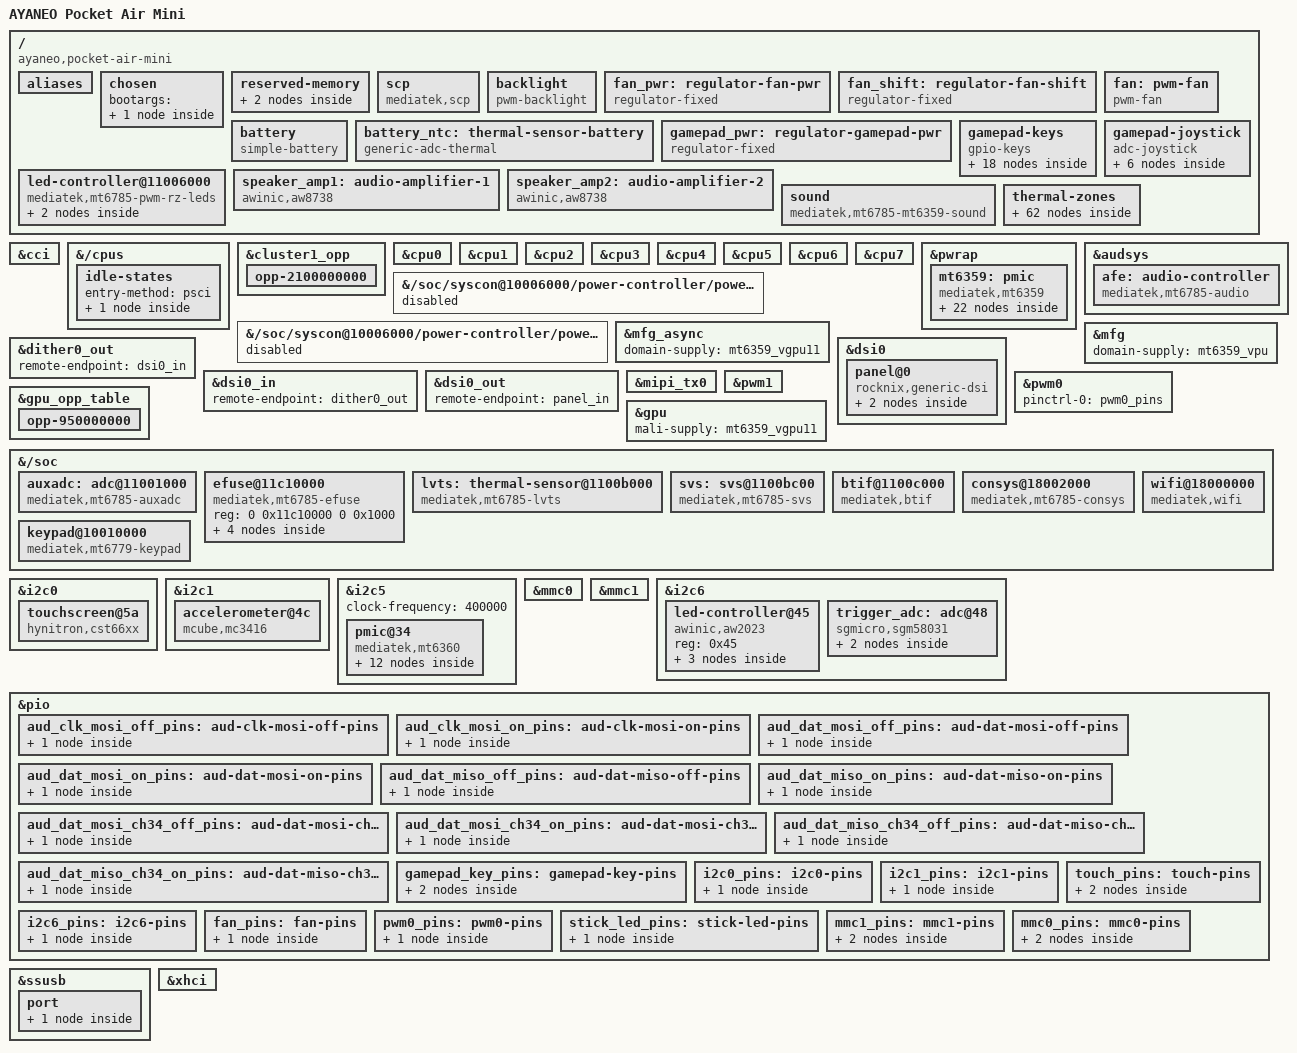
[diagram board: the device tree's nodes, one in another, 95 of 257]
// SPDX-License-Identifier: (GPL-2.0 OR MIT)
/dts-v1/;

#include <dt-bindings/gpio/gpio.h>
#include <dt-bindings/iio/adc/mediatek,mt6359-auxadc.h>
#include <dt-bindings/input/input.h>
#include <dt-bindings/leds/common.h>
#include <dt-bindings/thermal/mediatek,lvts-thermal.h>
#include <dt-bindings/thermal/thermal.h>
#include <dt-bindings/usb/pd.h>

#include "mt6785.dtsi"

/ {
	model = "AYANEO Pocket Air Mini";
	compatible = "ayaneo,pocket-air-mini", "mediatek,mt6785";
	chassis-type = "handset";

	/* eMMC probe waits for vemc, so pin the numbering */
	aliases {
		mmc0 = &mmc0;
		mmc1 = &mmc1;
	};

	chosen {
		#address-cells = <2>;
		#size-cells = <2>;
		ranges;

		/* needed by Little Kernel */
		bootargs = "";

		/* reg, stride and height are patched in by the custom LK (fdt_fixup_simplefb) */
		framebuffer0: framebuffer@7ed90000 {
			compatible = "simple-framebuffer";
			reg = <0 0x7ed90000 0 0x1070000>;
			width = <1280>;
			height = <3366>;
			stride = <(1280 * 4)>;
			format = "a8r8g8b8";
		};
	};

	/*
	 * No static reg nodes: LK appends its mblock-* regions here and hangs if one
	 * overlaps them. Dynamic size/alloc-ranges nodes are not checked.
	 */
	reserved-memory {
		#address-cells = <2>;
		#size-cells = <2>;
		ranges;

		consys_mem: consys-reserve-memory {
			compatible = "mediatek,consys-reserve-memory";
			no-map;
			size = <0 0x400000>;
			alignment = <0 0x1000000>;
			alloc-ranges = <0 0x40000000 0 0x80000000>;
		};

		wifi_mem: wifi-reserve-memory {
			compatible = "shared-dma-pool";
			no-map;
			size = <0 0x300000>;
			alignment = <0 0x1000000>;
			alloc-ranges = <0 0x40000000 0 0x80000000>;
		};
	};

	/* needed by Little Kernel */
	scp {
		compatible = "mediatek,scp";
	};

	/* DISP_PWM (GPIO42), keeping LK's 25.4 kHz */
	backlight: backlight {
		compatible = "pwm-backlight";
		pwms = <&pwm1 0 39385>;
		brightness-levels = <0 1023>;
		num-interpolated-steps = <1023>;
		default-brightness-level = <1023>;
	};

	/* fan power (GPIO22) feeds the level shifter enable (GPIO23) */
	fan_pwr: regulator-fan-pwr {
		compatible = "regulator-fixed";
		regulator-name = "fan_pwr";
		gpio = <&pio 22 GPIO_ACTIVE_HIGH>;
		enable-active-high;
	};

	fan_shift: regulator-fan-shift {
		compatible = "regulator-fixed";
		regulator-name = "fan_shift";
		gpio = <&pio 23 GPIO_ACTIVE_HIGH>;
		enable-active-high;
		vin-supply = <&fan_pwr>;
	};

	/* stock 1 kHz PWM, full speed for 50 ms to spin up */
	fan: pwm-fan {
		compatible = "pwm-fan";
		pwms = <&pwm0 0 1000000 0>;
		fan-supply = <&fan_shift>;
		interrupts-extended = <&pio 40 IRQ_TYPE_EDGE_FALLING>;
		pulses-per-revolution = <2>;
		fan-stop-to-start-percent = <100>;
		fan-stop-to-start-us = <50000>;
		#cooling-cells = <2>;
		cooling-levels = <0 77 128 191 255>;
		pinctrl-names = "default";
		pinctrl-0 = <&fan_pins>;
	};

	/* stock bat_gm30 and charger values, OCV from the 25 C profile */
	battery: battery {
		compatible = "simple-battery";
		device-chemistry = "lithium-ion";
		charge-full-design-microamp-hours = <4600000>;
		voltage-min-design-microvolt = <3400000>;
		voltage-max-design-microvolt = <4350000>;
		constant-charge-current-max-microamp = <2500000>;
		constant-charge-voltage-max-microvolt = <4350000>;
		charge-term-current-microamp = <150000>;
		precharge-current-microamp = <150000>;
		factory-internal-resistance-micro-ohms = <144000>;
		operating-range-celsius = <0 55>;
		ocv-capacity-celsius = <25>;
		ocv-capacity-table-0 = <4344900 100>,
				       <4257571 95>,
				       <4201313 90>,
				       <4147029 85>,
				       <4093285 80>,
				       <4048625 75>,
				       <3981883 70>,
				       <3939884 65>,
				       <3906996 60>,
				       <3866678 55>,
				       <3835200 50>,
				       <3811263 45>,
				       <3791581 40>,
				       <3775185 35>,
				       <3762021 30>,
				       <3749925 25>,
				       <3733298 20>,
				       <3709250 15>,
				       <3678882 10>,
				       <3656914 5>,
				       <3433700 0>;
	};

	/* 10k NTC with a 24k pull-up to VBIF28, AUXADC value in mV * 4096 */
	battery_ntc: thermal-sensor-battery {
		compatible = "generic-adc-thermal";
		#thermal-sensor-cells = <0>;
		io-channels = <&mt6359_auxadc MT6359_AUXADC_BAT_TEMP>;
		io-channel-names = "sensor-channel";
		temperature-lookup-table = <(-40000) 10215676>,
					   <(-35000) 9870092>,
					   <(-30000) 9464743>,
					   <(-25000) 9001485>,
					   <(-20000) 8484627>,
					   <(-15000) 7924032>,
					   <(-10000) 7330058>,
					   <(-5000) 6714236>,
					   <0 6094794>,
					   <5000 5487809>,
					   <10000 4903633>,
					   <15000 4351584>,
					   <20000 3840098>,
					   <25000 3373176>,
					   <30000 2951047>,
					   <35000 2574810>,
					   <40000 2242709>,
					   <45000 1950136>,
					   <50000 1694602>,
					   <55000 1472388>,
					   <60000 1279594>;
	};

	/* gamepad power, sequenced like the stock mtk-gamepad probe */
	gamepad_pwr: regulator-gamepad-pwr {
		compatible = "regulator-fixed";
		regulator-name = "gamepad_pwr";
		gpio = <&pio 15 GPIO_ACTIVE_HIGH>;
		enable-active-high;
		startup-delay-us = <100000>;
		vin-supply = <&mt6360_vfp>;
		regulator-always-on;
	};

	/* Start/Select codes as stock, D-pad as buttons */
	gamepad-keys {
		compatible = "gpio-keys";
		label = "Pocket Air Mini Buttons";
		pinctrl-names = "default";
		pinctrl-0 = <&gamepad_key_pins>;

		button-a {
			label = "a";
			linux,code = <BTN_SOUTH>;
			gpios = <&pio 82 GPIO_ACTIVE_LOW>;
		};

		button-b {
			label = "b";
			linux,code = <BTN_EAST>;
			gpios = <&pio 83 GPIO_ACTIVE_LOW>;
		};

		button-x {
			label = "x";
			linux,code = <BTN_NORTH>;
			gpios = <&pio 84 GPIO_ACTIVE_LOW>;
		};

		button-y {
			label = "y";
			linux,code = <BTN_WEST>;
			gpios = <&pio 85 GPIO_ACTIVE_LOW>;
		};

		button-lb {
			label = "lb";
			linux,code = <BTN_TL>;
			gpios = <&pio 92 GPIO_ACTIVE_LOW>;
		};

		button-rb {
			label = "rb";
			linux,code = <BTN_TR>;
			gpios = <&pio 81 GPIO_ACTIVE_LOW>;
		};

		button-l3 {
			label = "l3";
			linux,code = <BTN_THUMBL>;
			gpios = <&pio 94 GPIO_ACTIVE_LOW>;
		};

		button-r3 {
			label = "r3";
			linux,code = <BTN_THUMBR>;
			gpios = <&pio 93 GPIO_ACTIVE_LOW>;
		};

		button-select {
			label = "select";
			linux,code = <BTN_SELECT>;
			gpios = <&pio 90 GPIO_ACTIVE_LOW>;
		};

		button-start {
			label = "start";
			linux,code = <BTN_START>;
			gpios = <&pio 91 GPIO_ACTIVE_LOW>;
		};

		button-dpad-up {
			label = "dpad-up";
			linux,code = <BTN_DPAD_UP>;
			gpios = <&pio 89 GPIO_ACTIVE_LOW>;
		};

		button-dpad-down {
			label = "dpad-down";
			linux,code = <BTN_DPAD_DOWN>;
			gpios = <&pio 79 GPIO_ACTIVE_LOW>;
		};

		button-dpad-left {
			label = "dpad-left";
			linux,code = <BTN_DPAD_LEFT>;
			gpios = <&pio 78 GPIO_ACTIVE_LOW>;
		};

		button-dpad-right {
			label = "dpad-right";
			linux,code = <BTN_DPAD_RIGHT>;
			gpios = <&pio 80 GPIO_ACTIVE_LOW>;
		};

		button-aya {
			label = "aya";
			linux,code = <BTN_MODE>;
			gpios = <&pio 86 GPIO_ACTIVE_LOW>;
		};

		button-extra {
			label = "extra";
			linux,code = <BTN_TRIGGER_HAPPY1>;
			gpios = <&pio 87 GPIO_ACTIVE_LOW>;
		};

		button-lc {
			label = "lc";
			linux,code = <BTN_TRIGGER_HAPPY2>;
			gpios = <&pio 58 GPIO_ACTIVE_LOW>;
		};

		button-rc {
			label = "rc";
			linux,code = <BTN_TRIGGER_HAPPY3>;
			gpios = <&pio 57 GPIO_ACTIVE_LOW>;
		};
	};

	/* sticks on AUXADC 1-4, hall triggers on the SGM58031; Y axes and RT read inverted */
	gamepad-joystick {
		compatible = "adc-joystick";
		io-channels = <&auxadc 1>, <&auxadc 2>, <&auxadc 3>, <&auxadc 4>,
			      <&trigger_adc 4>, <&trigger_adc 5>;
		poll-interval = <8>;
		#address-cells = <1>;
		#size-cells = <0>;

		axis@0 {
			reg = <0>;
			linux,code = <ABS_X>;
			abs-range = <1170 3270>;
			abs-fuzz = <16>;
			abs-flat = <80>;
		};

		axis@1 {
			reg = <1>;
			linux,code = <ABS_Y>;
			abs-range = <3070 1170>;
			abs-fuzz = <16>;
			abs-flat = <80>;
		};

		axis@2 {
			reg = <2>;
			linux,code = <ABS_RX>;
			abs-range = <1094 3294>;
			abs-fuzz = <16>;
			abs-flat = <80>;
		};

		axis@3 {
			reg = <3>;
			linux,code = <ABS_RY>;
			abs-range = <3125 1145>;
			abs-fuzz = <16>;
			abs-flat = <80>;
		};

		axis@4 {
			reg = <4>;
			linux,code = <ABS_Z>;
			abs-range = <13700 16500>;
			abs-fuzz = <32>;
			abs-flat = <0>;
		};

		axis@5 {
			reg = <5>;
			linux,code = <ABS_RZ>;
			abs-range = <12550 10600>;
			abs-fuzz = <32>;
			abs-flat = <0>;
		};
	};

	/*
	 * 8 WS2812-style LEDs per stick ring on PWM_1 (left) and PWM_2 (right), in the
	 * PWM block shared with pwm-mediatek (fan on PWM_0)
	 */
	led-controller@11006000 {
		compatible = "mediatek,mt6785-pwm-rz-leds";
		reg = <0 0x11006000 0 0x1000>;
		clocks = <&infracfg CLK_INFRA_PWM>,
			 <&infracfg CLK_INFRA_PWM_HCLK>,
			 <&infracfg CLK_INFRA_PWM2>,
			 <&infracfg CLK_INFRA_PWM3>;
		clock-names = "top", "main", "pwm2", "pwm3";
		power-gpios = <&pio 127 GPIO_ACTIVE_HIGH>;
		enable-gpios = <&pio 202 GPIO_ACTIVE_HIGH>;
		pinctrl-names = "default";
		pinctrl-0 = <&stick_led_pins>;
		#address-cells = <1>;
		#size-cells = <0>;

		led@1 {
			reg = <1>;
			mediatek,num-leds = <8>;
			color = <LED_COLOR_ID_RGB>;
			function = "left-stick";
		};

		led@2 {
			reg = <2>;
			mediatek,num-leds = <8>;
			color = <LED_COLOR_ID_RGB>;
			function = "right-stick";
		};
	};

	/* two one-wire amps on the MT6359 headphone outputs, pulsed twice on enable */
	speaker_amp1: audio-amplifier-1 {
		compatible = "awinic,aw8738";
		mode-gpios = <&pio 24 GPIO_ACTIVE_HIGH>;
		awinic,mode = <2>;
		sound-name-prefix = "Speaker 1";
	};

	speaker_amp2: audio-amplifier-2 {
		compatible = "awinic,aw8738";
		mode-gpios = <&pio 21 GPIO_ACTIVE_HIGH>;
		awinic,mode = <2>;
		sound-name-prefix = "Speaker 2";
	};

	sound {
		compatible = "mediatek,mt6785-mt6359-sound";
		model = "PocketAirMini";
		mediatek,platform = <&afe>;
		mediatek,accdet = <&accdet>;
		aux-devs = <&speaker_amp1>, <&speaker_amp2>;
		audio-routing =
			"Headphone Jack", "Headphone L",
			"Headphone Jack", "Headphone R",
			"Speaker 1 IN", "Headphone L Ext Spk Amp",
			"Speaker 2 IN", "Headphone R Ext Spk Amp",
			"Speakers", "Speaker 1 OUT",
			"Speakers", "Speaker 2 OUT",
			"AIN0", "Internal Mic",
			"AIN1", "Headset Mic";
		pinctrl-names = "aud_clk_mosi_off", "aud_clk_mosi_on",
				"aud_dat_mosi_off", "aud_dat_mosi_on",
				"aud_dat_miso_off", "aud_dat_miso_on",
				"aud_dat_mosi_ch34_off", "aud_dat_mosi_ch34_on",
				"aud_dat_miso_ch34_off", "aud_dat_miso_ch34_on";
		pinctrl-0 = <&aud_clk_mosi_off_pins>;
		pinctrl-1 = <&aud_clk_mosi_on_pins>;
		pinctrl-2 = <&aud_dat_mosi_off_pins>;
		pinctrl-3 = <&aud_dat_mosi_on_pins>;
		pinctrl-4 = <&aud_dat_miso_off_pins>;
		pinctrl-5 = <&aud_dat_miso_on_pins>;
		pinctrl-6 = <&aud_dat_mosi_ch34_off_pins>;
		pinctrl-7 = <&aud_dat_mosi_ch34_on_pins>;
		pinctrl-8 = <&aud_dat_miso_ch34_off_pins>;
		pinctrl-9 = <&aud_dat_miso_ch34_on_pins>;
	};

	thermal-zones {
		battery-thermal {
			polling-delay-passive = <0>;
			polling-delay = <5000>;
			thermal-sensors = <&battery_ntc>;
		};

		cpu-big0-thermal {
			polling-delay-passive = <100>;
			polling-delay = <1000>;
			thermal-sensors = <&lvts MT6785_BIG_CPU0>;

			trips {
				big0_fan0: trip-fan0 {
					temperature = <55000>;
					hysteresis = <5000>;
					type = "active";
				};

				big0_fan1: trip-fan1 {
					temperature = <62000>;
					hysteresis = <5000>;
					type = "active";
				};

				big0_fan2: trip-fan2 {
					temperature = <69000>;
					hysteresis = <5000>;
					type = "active";
				};

				big0_fan3: trip-fan3 {
					temperature = <76000>;
					hysteresis = <5000>;
					type = "active";
				};

				big0_alert: trip-alert {
					temperature = <85000>;
					hysteresis = <2000>;
					type = "passive";
				};

				trip-crit {
					temperature = <117000>;
					hysteresis = <0>;
					type = "critical";
				};
			};

			cooling-maps {
				map0 {
					trip = <&big0_alert>;
					cooling-device = <&cpu6 THERMAL_NO_LIMIT THERMAL_NO_LIMIT>,
							 <&cpu7 THERMAL_NO_LIMIT THERMAL_NO_LIMIT>;
				};

				map1 {
					trip = <&big0_fan0>;
					cooling-device = <&fan 1 1>;
				};

				map2 {
					trip = <&big0_fan1>;
					cooling-device = <&fan 2 2>;
				};

				map3 {
					trip = <&big0_fan2>;
					cooling-device = <&fan 3 3>;
				};

				map4 {
					trip = <&big0_fan3>;
					cooling-device = <&fan 4 4>;
				};
			};
		};

		cpu-big1-thermal {
			polling-delay-passive = <100>;
			polling-delay = <1000>;
			thermal-sensors = <&lvts MT6785_BIG_CPU1>;

			trips {
				big1_alert: trip-alert {
					temperature = <85000>;
					hysteresis = <2000>;
					type = "passive";
				};

				trip-crit {
					temperature = <117000>;
					hysteresis = <0>;
					type = "critical";
				};
			};

			cooling-maps {
				map0 {
					trip = <&big1_alert>;
					cooling-device = <&cpu6 THERMAL_NO_LIMIT THERMAL_NO_LIMIT>,
							 <&cpu7 THERMAL_NO_LIMIT THERMAL_NO_LIMIT>;
				};
			};
		};

		cpu-little0-thermal {
			polling-delay-passive = <100>;
			polling-delay = <1000>;
			thermal-sensors = <&lvts MT6785_LITTLE_CPU0>;

			trips {
				little0_alert: trip-alert {
					temperature = <85000>;
					hysteresis = <2000>;
					type = "passive";
				};

				trip-crit {
					temperature = <117000>;
					hysteresis = <0>;
					type = "critical";
				};
			};

			cooling-maps {
				map0 {
					trip = <&little0_alert>;
					cooling-device = <&cpu0 THERMAL_NO_LIMIT THERMAL_NO_LIMIT>,
							 <&cpu1 THERMAL_NO_LIMIT THERMAL_NO_LIMIT>,
							 <&cpu2 THERMAL_NO_LIMIT THERMAL_NO_LIMIT>,
							 <&cpu3 THERMAL_NO_LIMIT THERMAL_NO_LIMIT>,
							 <&cpu4 THERMAL_NO_LIMIT THERMAL_NO_LIMIT>,
							 <&cpu5 THERMAL_NO_LIMIT THERMAL_NO_LIMIT>;
				};
			};
		};

		cpu-little1-thermal {
			polling-delay-passive = <100>;
			polling-delay = <1000>;
			thermal-sensors = <&lvts MT6785_LITTLE_CPU1>;

			trips {
				little1_alert: trip-alert {
					temperature = <85000>;
					hysteresis = <2000>;
					type = "passive";
				};

				trip-crit {
					temperature = <117000>;
					hysteresis = <0>;
					type = "critical";
				};
			};

			cooling-maps {
				map0 {
					trip = <&little1_alert>;
					cooling-device = <&cpu0 THERMAL_NO_LIMIT THERMAL_NO_LIMIT>,
							 <&cpu1 THERMAL_NO_LIMIT THERMAL_NO_LIMIT>,
							 <&cpu2 THERMAL_NO_LIMIT THERMAL_NO_LIMIT>,
							 <&cpu3 THERMAL_NO_LIMIT THERMAL_NO_LIMIT>,
							 <&cpu4 THERMAL_NO_LIMIT THERMAL_NO_LIMIT>,
							 <&cpu5 THERMAL_NO_LIMIT THERMAL_NO_LIMIT>;
				};
			};
		};

		cpu-little2-thermal {
			polling-delay-passive = <100>;
			polling-delay = <1000>;
			thermal-sensors = <&lvts MT6785_LITTLE_CPU2>;

			trips {
				little2_alert: trip-alert {
					temperature = <85000>;
					hysteresis = <2000>;
					type = "passive";
				};

				trip-crit {
					temperature = <117000>;
					hysteresis = <0>;
					type = "critical";
				};
			};

			cooling-maps {
				map0 {
					trip = <&little2_alert>;
					cooling-device = <&cpu0 THERMAL_NO_LIMIT THERMAL_NO_LIMIT>,
							 <&cpu1 THERMAL_NO_LIMIT THERMAL_NO_LIMIT>,
							 <&cpu2 THERMAL_NO_LIMIT THERMAL_NO_LIMIT>,
							 <&cpu3 THERMAL_NO_LIMIT THERMAL_NO_LIMIT>,
							 <&cpu4 THERMAL_NO_LIMIT THERMAL_NO_LIMIT>,
							 <&cpu5 THERMAL_NO_LIMIT THERMAL_NO_LIMIT>;
				};
			};
		};

		gpu0-thermal {
			polling-delay-passive = <100>;
			polling-delay = <1000>;
			thermal-sensors = <&lvts MT6785_GPU0>;

			trips {
				gpu0_fan0: trip-fan0 {
					temperature = <55000>;
					hysteresis = <5000>;
					type = "active";
				};

				gpu0_fan1: trip-fan1 {
					temperature = <62000>;
					hysteresis = <5000>;
					type = "active";
				};

				gpu0_fan2: trip-fan2 {
					temperature = <69000>;
					hysteresis = <5000>;
					type = "active";
				};

				gpu0_fan3: trip-fan3 {
					temperature = <76000>;
					hysteresis = <5000>;
					type = "active";
				};

				gpu0_alert: trip-alert {
					temperature = <85000>;
					hysteresis = <2000>;
					type = "passive";
				};

				trip-crit {
					temperature = <117000>;
					hysteresis = <0>;
					type = "critical";
				};
			};

			cooling-maps {
				map0 {
					trip = <&gpu0_alert>;
					cooling-device = <&gpu THERMAL_NO_LIMIT THERMAL_NO_LIMIT>;
				};

				map1 {
					trip = <&gpu0_fan0>;
					cooling-device = <&fan 1 1>;
				};

				map2 {
					trip = <&gpu0_fan1>;
					cooling-device = <&fan 2 2>;
				};

				map3 {
					trip = <&gpu0_fan2>;
					cooling-device = <&fan 3 3>;
				};

				map4 {
					trip = <&gpu0_fan3>;
					cooling-device = <&fan 4 4>;
				};
			};
		};

		gpu1-thermal {
			polling-delay-passive = <100>;
			polling-delay = <1000>;
			thermal-sensors = <&lvts MT6785_GPU1>;

			trips {
				gpu1_alert: trip-alert {
					temperature = <85000>;
					hysteresis = <2000>;
					type = "passive";
				};

				trip-crit {
					temperature = <117000>;
					hysteresis = <0>;
					type = "critical";
				};
			};

			cooling-maps {
				map0 {
					trip = <&gpu1_alert>;
					cooling-device = <&gpu THERMAL_NO_LIMIT THERMAL_NO_LIMIT>;
				};
			};
		};

		vpu-thermal {
			polling-delay-passive = <100>;
			polling-delay = <1000>;
			thermal-sensors = <&lvts MT6785_VPU>;

			trips {
				trip-crit {
					temperature = <117000>;
					hysteresis = <0>;
					type = "critical";
				};
			};
		};
	};
};

/* A55 cluster and CCI share vproc2, the A76 cluster has vproc1 */
&cci {
	proc-supply = <&mt6359_vproc2>;
	sram-supply = <&mt6359_vsram_proc2>;
};

/* cpu-off only, cluster-off hangs the SoC without the SSPM MCDI firmware */
&{/cpus} {
	idle-states {
		entry-method = "psci";

		cpu_off: cpu-off {
			compatible = "arm,idle-state";
			arm,psci-suspend-param = <0x00010001>;
			local-timer-stop;
			entry-latency-us = <600>;
			exit-latency-us = <600>;
			min-residency-us = <1200>;
		};
	};
};

/* stock big-core top OPP is 2.1 GHz, not 2.05 GHz */
&cluster1_opp {
	/delete-node/ opp-2050000000;

	opp-2100000000 {
		opp-hz = /bits/ 64 <2100000000>;
		opp-microvolt = <1118750>;
		required-opps = <&cci_opp_15>;
	};
};

&cpu0 {
	#cooling-cells = <2>;
	cpu-idle-states = <&cpu_off>;
	proc-supply = <&mt6359_vproc2>;
	sram-supply = <&mt6359_vsram_proc2>;
};

&cpu1 {
	#cooling-cells = <2>;
	cpu-idle-states = <&cpu_off>;
	proc-supply = <&mt6359_vproc2>;
	sram-supply = <&mt6359_vsram_proc2>;
};

&cpu2 {
	#cooling-cells = <2>;
	cpu-idle-states = <&cpu_off>;
	proc-supply = <&mt6359_vproc2>;
	sram-supply = <&mt6359_vsram_proc2>;
};

&cpu3 {
	#cooling-cells = <2>;
	cpu-idle-states = <&cpu_off>;
	proc-supply = <&mt6359_vproc2>;
	sram-supply = <&mt6359_vsram_proc2>;
};

&cpu4 {
	#cooling-cells = <2>;
	cpu-idle-states = <&cpu_off>;
	proc-supply = <&mt6359_vproc2>;
	sram-supply = <&mt6359_vsram_proc2>;
};

&cpu5 {
	#cooling-cells = <2>;
	cpu-idle-states = <&cpu_off>;
	proc-supply = <&mt6359_vproc2>;
	sram-supply = <&mt6359_vsram_proc2>;
};

&cpu6 {
	#cooling-cells = <2>;
	cpu-idle-states = <&cpu_off>;
	proc-supply = <&mt6359_vproc1>;
	sram-supply = <&mt6359_vsram_proc1>;
};

&cpu7 {
	#cooling-cells = <2>;
	cpu-idle-states = <&cpu_off>;
	proc-supply = <&mt6359_vproc1>;
	sram-supply = <&mt6359_vsram_proc1>;
};

/*
 * No power-off-time-sec or long-press-mode: mainline's TOP_RST_MISC is the
 * vendor's TOP_RST_MISC_SET, so the long-press reset stays as LK set it.
 */
&pwrap {
	mt6359: pmic {
		compatible = "mediatek,mt6359";
		interrupts-extended = <&pio 193 IRQ_TYPE_LEVEL_HIGH>;
		interrupt-controller;
		#interrupt-cells = <2>;

		/* RTC BBPU + PWRHOLD power-off (patches/0001) */
		power-controller {
			compatible = "mediatek,mt6359-pwrc";
		};

		rtc {
			compatible = "mediatek,mt6358-rtc";
		};

		/* only rails with a consumer, the rest stay undescribed so the kernel leaves them alone */
		regulators {
			/* CPU rails span the mt6785.dtsi OPPs, vsram tracks vproc + 100 mV as stock */
			mt6359_vproc1: buck_vproc1 {
				regulator-name = "vproc1";
				regulator-min-microvolt = <675000>;
				regulator-max-microvolt = <1118750>;
				regulator-ramp-delay = <7500>;
				regulator-always-on;
			};

			mt6359_vproc2: buck_vproc2 {
				regulator-name = "vproc2";
				regulator-min-microvolt = <600000>;
				regulator-max-microvolt = <1031250>;
				regulator-ramp-delay = <7500>;
				regulator-always-on;
			};

			mt6359_vsram_proc1: ldo_vsram_proc1 {
				regulator-name = "vsram_proc1";
				regulator-min-microvolt = <850000>;
				regulator-max-microvolt = <1118750>;
				regulator-ramp-delay = <7500>;
				regulator-always-on;
			};

			/*
			 * vpu serves as vsram_gpu, coupled at vgpu + 100 mV and at least 850 mV as
			 * stock; both may go off with the MFG domains
			 */
			mt6359_vgpu11: buck_vgpu11 {
				regulator-name = "vgpu";
				regulator-min-microvolt = <612500>;
				regulator-max-microvolt = <875000>;
				regulator-ramp-delay = <5000>;
				regulator-enable-ramp-delay = <200>;
				regulator-coupled-with = <&mt6359_vpu>;
				regulator-coupled-max-spread = <100000>;
			};

			mt6359_vpu: buck_vpu {
				regulator-name = "vsram_gpu";
				regulator-min-microvolt = <850000>;
				regulator-max-microvolt = <975000>;
				regulator-ramp-delay = <5000>;
				regulator-enable-ramp-delay = <200>;
				regulator-coupled-with = <&mt6359_vgpu11>;
				regulator-coupled-max-spread = <100000>;
			};

			mt6359_vsram_proc2: ldo_vsram_proc2 {
				regulator-name = "vsram_proc2";
				regulator-min-microvolt = <850000>;
				regulator-max-microvolt = <1118750>;
				regulator-ramp-delay = <7500>;
				regulator-always-on;
			};

			mt6359_vemc: ldo_vemc {
				regulator-name = "vemc";
				regulator-min-microvolt = <3000000>;
				regulator-max-microvolt = <3000000>;
				regulator-always-on;
			};

			mt6359_vusb: ldo_vusb {
				regulator-name = "vusb";
				regulator-min-microvolt = <3000000>;
				regulator-max-microvolt = <3000000>;
				regulator-always-on;
			};

			mt6359_vio18: ldo_vio18 {
				regulator-name = "vio18";
				regulator-min-microvolt = <1800000>;
				regulator-max-microvolt = <1800000>;
				regulator-always-on;
			};

			/* CONNSYS rails at the stock values with WiFi on */
			mt6359_vcn18: ldo_vcn18 {
				regulator-name = "vcn18";
				regulator-min-microvolt = <1800000>;
				regulator-max-microvolt = <1800000>;
			};

			mt6359_vcn33_1_wifi: ldo_vcn33_1_wifi {
				regulator-name = "vcn33_1_wifi";
				regulator-min-microvolt = <3300000>;
				regulator-max-microvolt = <3300000>;
			};

			mt6359_vcn33_2_wifi: ldo_vcn33_2_wifi {
				regulator-name = "vcn33_2_wifi";
				regulator-min-microvolt = <2800000>;
				regulator-max-microvolt = <2800000>;
			};

			/* battery NTC pull-up */
			mt6359_vbif28: ldo_vbif28 {
				regulator-name = "vbif28";
				regulator-min-microvolt = <2800000>;
				regulator-max-microvolt = <2800000>;
				regulator-always-on;
			};
		};

		/* the MT6359 codec driver only probes with this node */
		audio-codec {
		};

		/* stock accdet settings, 3-key headset on PMIC EINT0 */
		accdet: accdet {
			compatible = "mediatek,mt6359-accdet";
			mediatek,mic-vol = <8>;
			mediatek,plugout-debounce = <1>;
			mediatek,mic-mode = <2>;
			mediatek,pwm-deb-setting = <0x500 0x500 1 0x1f0 0x800 0x800 0x20 0x44
						    4 1 5 3 3 5 0xe>;
			mediatek,eint-use-ext-res = <0>;
			mediatek,three-key-thr = <0 80 220 400>;
		};

		mt6359_auxadc: adc {
			compatible = "mediatek,mt6359-auxadc";
			#io-channel-cells = <1>;
		};

		keys {
			compatible = "mediatek,mt6359-keys";

			power {
				linux,keycodes = <KEY_POWER>;
				wakeup-source;
			};

			home {
				linux,keycodes = <KEY_VOLUMEUP>;
			};
		};
	};
};

/*
 * scpsys fails as a whole if one domain does not power on. MD has no modem
 * rails and CONN is sequenced by the CONNSYS driver; the M4U needs the rest.
 */
&{/soc/syscon@10006000/power-controller/power-domain@2} {
	status = "disabled";
};

&{/soc/syscon@10006000/power-controller/power-domain@4} {
	status = "disabled";
};

&audsys {
	afe: audio-controller {
		compatible = "mediatek,mt6785-audio";
		interrupts = <GIC_SPI 184 IRQ_TYPE_LEVEL_LOW>;
		resets = <&watchdog MT6785_TOPRGU_AUDIO_RST>;
		reset-names = "audiosys";
		mediatek,topckgen = <&topckgen>;
		power-domains = <&spm MT6785_POWER_DOMAIN_AUDIO>;
		clocks = <&audsys CLK_AUD_AFE>,
			 <&audsys CLK_AUD_DAC>,
			 <&audsys CLK_AUD_DAC_PREDIS>,
			 <&audsys CLK_AUD_ADC>,
			 <&audsys CLK_AUD_ADDA6_ADC>,
			 <&audsys CLK_AUD_22M>,
			 <&audsys CLK_AUD_24M>,
			 <&audsys CLK_AUD_APLL_TUNER>,
			 <&audsys CLK_AUD_APLL2_TUNER>,
			 <&audsys CLK_AUD_TML>,
			 <&audsys CLK_AUD_NLE>,
			 <&audsys CLK_AUD_3RD_DAC>,
			 <&audsys CLK_AUD_3RD_DAC_PREDIS>,
			 <&infracfg CLK_INFRA_AUDIO>,
			 <&infracfg CLK_INFRA_AUDIO_26M>,
			 <&topckgen CLK_TOP_AUDIO>,
			 <&topckgen CLK_TOP_AUDIO_INTBUS>,
			 <&topckgen CLK_TOP_AUDIO1>,
			 <&apmixedsys CLK_APMIXED_APLL1>,
			 <&topckgen CLK_TOP_AUDIO2>,
			 <&apmixedsys CLK_APMIXED_APLL2>,
			 <&topckgen CLK_TOP_AUDIO_ENG1>,
			 <&topckgen CLK_TOP_APLL1_D8>,
			 <&topckgen CLK_TOP_AUDIO_ENG2>,
			 <&topckgen CLK_TOP_APLL2_D8>,
			 <&topckgen CLK_TOP_AUDIO_HIRES>,
			 <&clk26m>;
		clock-names = "aud_afe_clk",
			      "aud_dac_clk",
			      "aud_dac_predis_clk",
			      "aud_adc_clk",
			      "aud_adda6_adc_clk",
			      "aud_apll22m_clk",
			      "aud_apll24m_clk",
			      "aud_apll1_tuner_clk",
			      "aud_apll2_tuner_clk",
			      "aud_tml_clk",
			      "aud_nle",
			      "aud_3rd_dac_clk",
			      "aud_3rd_dac_predis_clk",
			      "aud_infra_clk",
			      "aud_infra_26m_clk",
			      "top_mux_audio",
			      "top_mux_audio_int",
			      "top_mux_aud_1",
			      "top_apll1_ck",
			      "top_mux_aud_2",
			      "top_apll2_ck",
			      "top_mux_aud_eng1",
			      "top_apll1_d8",
			      "top_mux_aud_eng2",
			      "top_apll2_d8",
			      "top_mux_audio_h",
			      "top_clk26m_clk";
	};
};

&mfg_async {
	domain-supply = <&mt6359_vgpu11>;
};

/* MFG holds the GPU SRAM */
&mfg {
	domain-supply = <&mt6359_vpu>;
};

/* OVL0 .. DITHER0 -> DSI0 as LK sets it up, panel supplies stay as LK left them */
&dither0_out {
	remote-endpoint = <&dsi0_in>;
};

&dsi0 {
	status = "okay";

	/*
	 * Stock st7703_hd720_lcm_drv: reset GPIO44, 1280x960 sync-pulse video at
	 * the stock 532 Mbps per lane; mt6785-dsi (patches/0002) programs LK's
	 * D-PHY timings and porches, so the link runs LK's 60.05 Hz. The clock
	 * lane must drop to LP between lines (LK's HSTX_CKLP_EN): with a
	 * continuous clock the panel shows only vertical lines. The I lines are
	 * the stock lk_a table byte
	 * for byte (VGH/VGL 0x58, CPUMP 0x32, AVDD 0xE0, AVEE 0x20); the source
	 * LK's default over-drives these. Commands >= 0xB0 go out as generic
	 * writes (gen=), the rest as DCS, as MTK's DSI_set_cmdq_V2 does. Waits
	 * are hex ms.
	 */
	panel@0 {
		compatible = "rocknix,generic-dsi";
		reg = <0>;
		backlight = <&backlight>;
		reset-gpios = <&pio 44 GPIO_ACTIVE_LOW>;

		panel_description =
			"G size=85,64 delays=10,10,120,20,0 format=rgb888 lanes=4 flags=0xc05",
			"M clock=88667 horizontal=1280,60,30,60 vertical=960,16,8,8 default=1",
			"I gen=ee01",
			"I gen=ea07",
			"I gen=eb12",
			"I dcs=05 data=19",
			"I dcs=0a data=86",
			"I dcs=14 data=58",
			"I dcs=15 data=58",
			"I dcs=17 data=32",
			"I dcs=28 data=1f",
			"I dcs=29 data=29",
			"I dcs=2a data=63",
			"I dcs=2f data=f3",
			"I gen=ee02",
			"I dcs=39 data=70",
			"I dcs=00 data=00",
			"I dcs=01 data=0d",
			"I dcs=02 data=14",
			"I dcs=03 data=09",
			"I dcs=04 data=10",
			"I dcs=05 data=4c",
			"I dcs=06 data=0b",
			"I dcs=07 data=11",
			"I dcs=08 data=0e",
			"I dcs=09 data=0d",
			"I dcs=0a data=11",
			"I dcs=0b data=5f",
			"I dcs=0c data=14",
			"I dcs=0d data=18",
			"I dcs=0e data=3e",
			"I dcs=0f data=3d",
			"I dcs=10 data=3f",
			"I dcs=20 data=00",
			"I dcs=21 data=0b",
			"I dcs=22 data=12",
			"I dcs=23 data=03",
			"I dcs=24 data=08",
			"I dcs=25 data=40",
			"I dcs=26 data=0b",
			"I dcs=27 data=09",
			"I dcs=28 data=0e",
			"I dcs=29 data=0d",
			"I dcs=2a data=11",
			"I dcs=2b data=5f",
			"I dcs=2c data=14",
			"I dcs=2d data=18",
			"I dcs=2e data=3e",
			"I dcs=2f data=3d",
			"I dcs=30 data=3f",
			"I gen=ee04",
			"I dcs=00 data=01",
			"I dcs=01 data=01",
			"I dcs=02 data=e0",
			"I dcs=03 data=05",
			"I dcs=04 data=00",
			"I dcs=06 data=14",
			"I dcs=07 data=05",
			"I dcs=08 data=12",
			"I dcs=09 data=20",
			"I dcs=0a data=0f",
			"I dcs=0b data=04",
			"I dcs=20 data=40",
			"I dcs=2a data=00",
			"I dcs=40 data=80",
			"I dcs=41 data=60",
			"I gen=ee05",
			"I dcs=00 data=05",
			"I dcs=01 data=09",
			"I dcs=02 data=05",
			"I dcs=03 data=05",
			"I dcs=07 data=01",
			"I dcs=08 data=05",
			"I dcs=09 data=00",
			"I dcs=10 data=08",
			"I dcs=11 data=0c",
			"I dcs=12 data=25",
			"I dcs=13 data=05",
			"I dcs=19 data=90",
			"I dcs=1a data=77",
			"I dcs=23 data=00",
			"I dcs=30 data=01",
			"I dcs=31 data=01",
			"I dcs=32 data=00",
			"I dcs=33 data=14",
			"I dcs=34 data=14",
			"I dcs=35 data=b4",
			"I dcs=36 data=01",
			"I dcs=37 data=01",
			"I dcs=38 data=00",
			"I dcs=39 data=14",
			"I dcs=3a data=14",
			"I dcs=40 data=00",
			"I dcs=41 data=00",
			"I dcs=43 data=11",
			"I dcs=44 data=01",
			"I dcs=45 data=81",
			"I dcs=46 data=06",
			"I dcs=47 data=03",
			"I gen=ee06",
			"I dcs=00 data=23",
			"I dcs=01 data=01",
			"I dcs=02 data=04",
			"I dcs=06 data=cd",
			"I dcs=08 data=67",
			"I dcs=09 data=45",
			"I dcs=0a data=23",
			"I dcs=0b data=01",
			"I gen=ee07",
			"I dcs=00 data=14",
			"I dcs=01 data=14",
			"I dcs=02 data=16",
			"I dcs=03 data=16",
			"I dcs=04 data=10",
			"I dcs=05 data=10",
			"I dcs=06 data=12",
			"I dcs=07 data=12",
			"I dcs=08 data=0d",
			"I dcs=09 data=0d",
			"I dcs=0a data=00",
			"I dcs=0b data=00",
			"I dcs=0c data=0c",
			"I dcs=0d data=0c",
			"I dcs=0e data=04",
			"I dcs=0f data=04",
			"I dcs=10 data=3c",
			"I dcs=11 data=3c",
			"I dcs=12 data=20",
			"I dcs=13 data=20",
			"I dcs=14 data=21",
			"I dcs=15 data=21",
			"I dcs=20 data=15",
			"I dcs=21 data=15",
			"I dcs=22 data=17",
			"I dcs=23 data=17",
			"I dcs=24 data=11",
			"I dcs=25 data=11",
			"I dcs=26 data=13",
			"I dcs=27 data=13",
			"I dcs=28 data=0d",
			"I dcs=29 data=0d",
			"I dcs=2a data=01",
			"I dcs=2b data=01",
			"I dcs=2c data=0c",
			"I dcs=2d data=0c",
			"I dcs=2e data=04",
			"I dcs=2f data=04",
			"I dcs=30 data=3c",
			"I dcs=31 data=3c",
			"I dcs=32 data=20",
			"I dcs=33 data=20",
			"I dcs=34 data=21",
			"I dcs=35 data=21",
			"I gen=ee08",
			"I dcs=12 data=da",
			"I dcs=13 data=9b",
			"I dcs=18 data=00",
			"I dcs=20 data=00",
			"I dcs=22 data=69",
			"I dcs=2c data=20",
			"I dcs=4b data=a0",
			"I dcs=61 data=20",
			"I gen=ee0f",
			"I dcs=00 data=01",
			"I gen=ee00",
			"I gen=ea00",
			"I gen=eb00",
			"I dcs=36 data=00",
			"I dcs=11 data=00 wait=3c",
			"I dcs=29 data=00 wait=a";

		port {
			panel_in: endpoint {
				remote-endpoint = <&dsi0_out>;
			};
		};
	};
};

&dsi0_in {
	remote-endpoint = <&dither0_out>;
};

&dsi0_out {
	remote-endpoint = <&panel_in>;
};

&mipi_tx0 {
	status = "okay";
};

&pwm0 {
	pinctrl-names = "default";
	pinctrl-0 = <&pwm0_pins>;
	status = "okay";
};

&pwm1 {
	status = "okay";
};

/* GammaOS tops the GPU at 950 MHz, not mt6785.dtsi's 900 MHz */
&gpu_opp_table {
	/delete-node/ opp-900000000;

	opp-950000000 {
		opp-hz = /bits/ 64 <950000000>;
		opp-microvolt = <875000>;
	};
};

&gpu {
	mali-supply = <&mt6359_vgpu11>;
	status = "okay";
};

&{/soc} {
	/* MT6765 register layout */
	auxadc: adc@11001000 {
		compatible = "mediatek,mt6785-auxadc", "mediatek,mt6765-auxadc";
		reg = <0 0x11001000 0 0x1000>;
		clocks = <&infracfg CLK_INFRA_AUXADC>;
		clock-names = "main";
		#io-channel-cells = <1>;
	};

	efuse@11c10000 {
		compatible = "mediatek,mt6785-efuse", "mediatek,efuse";
		reg = <0 0x11c10000 0 0x1000>;
		#address-cells = <1>;
		#size-cells = <1>;

		/* LVTS calibration: golden temp, count_r0..r7 */
		lvts_e_data1: lvts-golden@1b0 {
			reg = <0x1b0 0x4>;
		};

		lvts_e_data2: lvts-big@1c8 {
			reg = <0x1c8 0x8>;
		};

		/* EEM M_HW_RES0..24 */
		svs_calibration: svs-calib@580 {
			reg = <0x580 0x64>;
		};

		lvts_e_data3: lvts-others@93c {
			reg = <0x93c 0x18>;
		};
	};

	lvts: thermal-sensor@1100b000 {
		compatible = "mediatek,mt6785-lvts";
		reg = <0 0x1100b000 0 0x1000>;
		interrupts = <GIC_SPI 100 IRQ_TYPE_LEVEL_LOW>;
		clocks = <&infracfg CLK_INFRA_THERM>;
		resets = <&infracfg MT6785_INFRA_THERM_CTRL_RST>;
		nvmem-cells = <&lvts_e_data1>, <&lvts_e_data2>, <&lvts_e_data3>;
		nvmem-cell-names = "lvts-calib-data-1", "lvts-calib-data-2",
				   "lvts-calib-data-3";
		#thermal-sensor-cells = <1>;
	};

	/* EEM banks 0xc00 into the thermal block */
	svs: svs@1100bc00 {
		compatible = "mediatek,mt6785-svs";
		reg = <0 0x1100bc00 0 0x400>;
		interrupts = <GIC_SPI 150 IRQ_TYPE_LEVEL_LOW>;
		clocks = <&infracfg CLK_INFRA_THERM>;
		clock-names = "main";
		nvmem-cells = <&svs_calibration>, <&lvts_e_data1>;
		nvmem-cell-names = "svs-calibration-data", "t-calibration-data";
		resets = <&infracfg MT6785_INFRA_SVS_RST>;
		reset-names = "svs_rst";
	};

	/* BTIF + AP DMA: the STP link to CONNSYS for the downstream btif driver */
	btif@1100c000 {
		compatible = "mediatek,btif";
		reg = <0 0x1100c000 0 0x1000>,
		      <0 0x11000b80 0 0x80>,
		      <0 0x11000c00 0 0x80>;
		interrupts = <GIC_SPI 138 IRQ_TYPE_LEVEL_LOW>,
			     <GIC_SPI 155 IRQ_TYPE_LEVEL_LOW>,
			     <GIC_SPI 154 IRQ_TYPE_LEVEL_LOW>;
		clocks = <&infracfg CLK_INFRA_BTIF>, <&infracfg CLK_INFRA_AP_DMA>;
		clock-names = "btifc", "apdmac";
	};

	/* CONNSYS (WMT), register order as mt6785.h *_BASE_INDEX */
	consys@18002000 {
		compatible = "mediatek,mt6785-consys";
		reg = <0 0x18002000 0 0x1000>,
		      <0 0x10007000 0 0x100>,
		      <0 0x10001000 0 0x1000>,
		      <0 0x10006000 0 0x1000>,
		      <0 0x18007000 0 0x1000>,
		      <0 0x180b1000 0 0x1000>,
		      <0 0x180a3000 0 0x1000>,
		      <0 0x180a5000 0 0x800>,
		      <0 0x180c1000 0 0x1000>,
		      <0 0x18004000 0 0x1000>,
		      <0 0x1024c000 0 0x40>,
		      <0 0x10003000 0 0x1000>;
		interrupts = <GIC_SPI 321 IRQ_TYPE_LEVEL_LOW>,
			     <GIC_SPI 78 IRQ_TYPE_LEVEL_LOW>,
			     <GIC_SPI 323 IRQ_TYPE_EDGE_RISING>;
		clocks = <&infracfg CLK_INFRA_CCIF4_AP>;
		clock-names = "ccif";
		memory-region = <&consys_mem>;
		pmic = <&mt6359>;
		vcn18-supply = <&mt6359_vcn18>;
		vcn33_1_wifi-supply = <&mt6359_vcn33_1_wifi>;
		vcn33_2_wifi-supply = <&mt6359_vcn33_2_wifi>;
	};

	wifi@18000000 {
		compatible = "mediatek,wifi";
		reg = <0 0x18000000 0 0x100000>;
		interrupts = <GIC_SPI 322 IRQ_TYPE_LEVEL_LOW>;
		memory-region = <&wifi_mem>;
	};

	/* Vol Down is keypad matrix key 0, pins left as LK set them */
	keypad@10010000 {
		compatible = "mediatek,mt6779-keypad";
		reg = <0 0x10010000 0 0x1000>;
		interrupts = <GIC_SPI 75 IRQ_TYPE_EDGE_FALLING>;
		clocks = <&clk26m>;
		clock-names = "kpd";
		keypad,num-rows = <1>;
		keypad,num-columns = <1>;
		linux,keymap = <MATRIX_KEY(0, 0, KEY_VOLUMEDOWN)>;
	};
};

&i2c0 {
	clock-frequency = <400000>;
	pinctrl-names = "default";
	pinctrl-0 = <&i2c0_pins>;
	status = "okay";

	/* no axis swap, as stock */
	touchscreen@5a {
		compatible = "hynitron,cst66xx";
		reg = <0x5a>;
		interrupts-extended = <&pio 1 IRQ_TYPE_EDGE_FALLING>;
		reset-gpios = <&pio 2 GPIO_ACTIVE_LOW>;
		vdd-supply = <&mt6360_vtp>;
		touchscreen-size-x = <1280>;
		touchscreen-size-y = <960>;
		pinctrl-names = "default";
		pinctrl-0 = <&touch_pins>;
	};
};

&i2c1 {
	clock-frequency = <400000>;
	pinctrl-names = "default";
	pinctrl-0 = <&i2c1_pins>;
	status = "okay";

	/* polled, mount-matrix from the stock direction 5 */
	accelerometer@4c {
		compatible = "mcube,mc3416";
		reg = <0x4c>;
		mount-matrix = "0", "1", "0",
			       "1", "0", "0",
			       "0", "0", "-1";
	};
};

/* pins already muxed by LK, which drives the MT6360 itself */
&i2c5 {
	clock-frequency = <400000>;
	status = "okay";

	pmic@34 {
		compatible = "mediatek,mt6360";
		reg = <0x34>;
		interrupts-extended = <&pio 16 IRQ_TYPE_EDGE_FALLING>;
		interrupt-names = "IRQB";
		interrupt-controller;
		#interrupt-cells = <1>;

		mt6360_adc: adc {
			compatible = "mediatek,mt6360-adc";
			#io-channel-cells = <1>;
		};

		/* PDOs and Rp as stock */
		mt6360_tcpc: tcpc {
			compatible = "mediatek,mt6360-tcpc";
			interrupts-extended = <&pio 7 IRQ_TYPE_LEVEL_LOW>;
			interrupt-names = "PD_IRQB";
			vbus-supply = <&mt6360_otg_vbus>;

			connector {
				compatible = "usb-c-connector";
				label = "USB-C";
				data-role = "dual";
				power-role = "dual";
				try-power-role = "sink";
				typec-power-opmode = "1.5A";
				source-pdos = <PDO_FIXED(5000, 1500, PDO_FIXED_DUAL_ROLE |
							 PDO_FIXED_DATA_SWAP | PDO_FIXED_USB_COMM)>;
				sink-pdos = <PDO_FIXED(5000, 2600, PDO_FIXED_DUAL_ROLE |
						       PDO_FIXED_DATA_SWAP | PDO_FIXED_USB_COMM)>;
				op-sink-microwatt = <13000000>;

				port {
					typec_hs_ep: endpoint {
						remote-endpoint = <&ssusb_hs_ep>;
					};
				};
			};
		};

		/* stock charger settings */
		charger {
			compatible = "mediatek,mt6360-chg";
			/* no Pump Express on mainline: 5 V adapters only */
			richtek,vinovp-microvolt = <6500000>;
			monitored-battery = <&battery>;
			/* Type-C/PD current from TCPM; stock sinks 5 V 2.6 A */
			power-supplies = <&mt6360_tcpc>;
			mediatek,input-current-max-microamp = <2600000>;
			io-channels = <&mt6360_adc 4>, <&mt6360_adc 6>;
			io-channel-names = "vbat", "ibat";
			mediatek,battery-thermal-zone = "battery-thermal";
			mediatek,input-voltage-limit-microvolt = <4400000>;
			mediatek,safety-timer-hours = <12>;
			mediatek,ircomp-resistor-micro-ohms = <25000>;
			mediatek,ircomp-clamp-microvolt = <32000>;

			/* stock OTG boost voltage and current limit */
			mt6360_otg_vbus: usb-otg-vbus-regulator {
				regulator-name = "usb-otg-vbus";
				regulator-min-microvolt = <5050000>;
				regulator-max-microvolt = <5050000>;
				regulator-min-microamp = <500000>;
				regulator-max-microamp = <1800000>;
			};
		};

		regulator {
			compatible = "mediatek,mt6360-regulator";
			/* arm the vendor power-off sequence before power-off (patches/0001) */
			mediatek,poweroff-sequence;

			/* buck2/ldo6/ldo7 feed DRAM and stay undescribed */
			/* VFP: the gamepad's vcc3v3 */
			mt6360_vfp: ldo1 {
				regulator-name = "vfp";
				regulator-min-microvolt = <3300000>;
				regulator-max-microvolt = <3300000>;
			};

			/* VTP: the touch controller's vtouch, 2.8 V as stock */
			mt6360_vtp: ldo2 {
				regulator-name = "vtp";
				regulator-min-microvolt = <2800000>;
				regulator-max-microvolt = <2800000>;
			};

			mt6360_vmc: ldo3 {
				regulator-name = "vmc";
				regulator-min-microvolt = <1800000>;
				regulator-max-microvolt = <3000000>;
			};

			mt6360_vmch: ldo5 {
				regulator-name = "vmch";
				regulator-min-microvolt = <3000000>;
				regulator-max-microvolt = <3000000>;
			};
		};
	};
};

/* stock msdc0 caps without hw-reset, 1.8 V I/O from a fixed rail so no vqmmc */
&mmc0 {
	bus-width = <8>;
	max-frequency = <200000000>;
	cap-mmc-highspeed;
	mmc-ddr-1_8v;
	mmc-hs200-1_8v;
	mmc-hs400-1_8v;
	non-removable;
	no-sd;
	no-sdio;
	vmmc-supply = <&mt6359_vemc>;

	pinctrl-names = "default", "state_uhs";
	pinctrl-0 = <&mmc0_pins>;
	pinctrl-1 = <&mmc0_pins>;

	status = "okay";
};

/* stock msdc1 caps; card detect GPIO8 reads low with a card and needs no pin state */
&mmc1 {
	bus-width = <4>;
	max-frequency = <200000000>;
	cap-sd-highspeed;
	sd-uhs-sdr12;
	sd-uhs-sdr25;
	sd-uhs-sdr50;
	sd-uhs-sdr104;
	sd-uhs-ddr50;
	disable-wp;
	no-mmc;
	no-sdio;
	cd-gpios = <&pio 8 GPIO_ACTIVE_LOW>;
	vmmc-supply = <&mt6360_vmch>;
	vqmmc-supply = <&mt6360_vmc>;

	pinctrl-names = "default", "state_uhs";
	pinctrl-0 = <&mmc1_pins>;
	pinctrl-1 = <&mmc1_pins>;

	status = "okay";
};

/* the SGM58031 does not answer at 400 kHz on mainline timings */
&i2c6 {
	clock-frequency = <100000>;
	pinctrl-names = "default";
	pinctrl-0 = <&i2c6_pins>;
	status = "okay";

	/* AW2023, 1 mA per channel as stock */
	led-controller@45 {
		compatible = "awinic,aw2023";
		reg = <0x45>;
		#address-cells = <1>;
		#size-cells = <0>;

		led@0 {
			reg = <0>;
			color = <LED_COLOR_ID_RED>;
			function = LED_FUNCTION_INDICATOR;
			led-max-microamp = <1000>;
		};

		led@1 {
			reg = <1>;
			color = <LED_COLOR_ID_GREEN>;
			function = LED_FUNCTION_INDICATOR;
			led-max-microamp = <1000>;
		};

		led@2 {
			reg = <2>;
			color = <LED_COLOR_ID_BLUE>;
			function = LED_FUNCTION_INDICATOR;
			led-max-microamp = <1000>;
		};
	};

	/* SGM58031 (ADS1115 clone): AIN0 is LT, AIN1 is RT, 4.096 V range */
	trigger_adc: adc@48 {
		compatible = "sgmicro,sgm58031", "ti,ads1115";
		reg = <0x48>;
		vdd-supply = <&gamepad_pwr>;
		#address-cells = <1>;
		#size-cells = <0>;
		#io-channel-cells = <1>;

		channel@4 {
			reg = <4>;
			ti,gain = <1>;
			ti,datarate = <7>;
		};

		channel@5 {
			reg = <5>;
			ti,gain = <1>;
			ti,datarate = <7>;
		};
	};
};

&pio {
	/* MT6359 mtkaif: GPIO with pull-down when idle, as stock */
	aud_clk_mosi_off_pins: aud-clk-mosi-off-pins {
		pins-cmd-dat {
			pinmux = <PINMUX_GPIO189__FUNC_GPIO189>,
				 <PINMUX_GPIO190__FUNC_GPIO190>;
			input-enable;
			bias-pull-down;
		};
	};

	aud_clk_mosi_on_pins: aud-clk-mosi-on-pins {
		pins-cmd-dat {
			pinmux = <PINMUX_GPIO189__FUNC_AUD_CLK_MOSI>,
				 <PINMUX_GPIO190__FUNC_AUD_SYNC_MOSI>;
			input-schmitt-enable;
			bias-disable;
		};
	};

	aud_dat_mosi_off_pins: aud-dat-mosi-off-pins {
		pins-cmd-dat {
			pinmux = <PINMUX_GPIO191__FUNC_GPIO191>,
				 <PINMUX_GPIO192__FUNC_GPIO192>;
			input-enable;
			bias-pull-down;
		};
	};

	aud_dat_mosi_on_pins: aud-dat-mosi-on-pins {
		pins-cmd-dat {
			pinmux = <PINMUX_GPIO191__FUNC_AUD_DAT_MOSI0>,
				 <PINMUX_GPIO192__FUNC_AUD_DAT_MOSI1>;
			input-schmitt-enable;
			bias-disable;
		};
	};

	aud_dat_miso_off_pins: aud-dat-miso-off-pins {
		pins-cmd-dat {
			pinmux = <PINMUX_GPIO193__FUNC_GPIO193>,
				 <PINMUX_GPIO194__FUNC_GPIO194>;
			input-enable;
			bias-pull-down;
		};
	};

	aud_dat_miso_on_pins: aud-dat-miso-on-pins {
		pins-cmd-dat {
			pinmux = <PINMUX_GPIO193__FUNC_AUD_DAT_MISO0>,
				 <PINMUX_GPIO194__FUNC_AUD_DAT_MISO1>;
			input-schmitt-enable;
			bias-disable;
		};
	};

	aud_dat_mosi_ch34_off_pins: aud-dat-mosi-ch34-off-pins {
		pins-cmd-dat {
			pinmux = <PINMUX_GPIO143__FUNC_GPIO143>;
			input-enable;
			bias-pull-down;
		};
	};

	aud_dat_mosi_ch34_on_pins: aud-dat-mosi-ch34-on-pins {
		pins-cmd-dat {
			pinmux = <PINMUX_GPIO143__FUNC_AUD_DAT_MOSI2>;
			input-schmitt-enable;
			bias-disable;
		};
	};

	aud_dat_miso_ch34_off_pins: aud-dat-miso-ch34-off-pins {
		pins-cmd-dat {
			pinmux = <PINMUX_GPIO146__FUNC_GPIO146>;
			input-enable;
			bias-pull-down;
		};
	};

	aud_dat_miso_ch34_on_pins: aud-dat-miso-ch34-on-pins {
		pins-cmd-dat {
			pinmux = <PINMUX_GPIO146__FUNC_AUD_DAT_MISO2>;
			input-schmitt-enable;
			bias-disable;
		};
	};

	/* stock pulls */
	gamepad_key_pins: gamepad-key-pins {
		pins-keys {
			pinmux = <PINMUX_GPIO78__FUNC_GPIO78>,
				 <PINMUX_GPIO79__FUNC_GPIO79>,
				 <PINMUX_GPIO80__FUNC_GPIO80>,
				 <PINMUX_GPIO81__FUNC_GPIO81>,
				 <PINMUX_GPIO82__FUNC_GPIO82>,
				 <PINMUX_GPIO83__FUNC_GPIO83>,
				 <PINMUX_GPIO84__FUNC_GPIO84>,
				 <PINMUX_GPIO85__FUNC_GPIO85>,
				 <PINMUX_GPIO86__FUNC_GPIO86>,
				 <PINMUX_GPIO87__FUNC_GPIO87>,
				 <PINMUX_GPIO89__FUNC_GPIO89>,
				 <PINMUX_GPIO90__FUNC_GPIO90>,
				 <PINMUX_GPIO91__FUNC_GPIO91>,
				 <PINMUX_GPIO92__FUNC_GPIO92>,
				 <PINMUX_GPIO93__FUNC_GPIO93>,
				 <PINMUX_GPIO94__FUNC_GPIO94>;
			input-enable;
			bias-pull-up;
		};

		pins-keys-pupd {
			pinmux = <PINMUX_GPIO57__FUNC_GPIO57>,
				 <PINMUX_GPIO58__FUNC_GPIO58>;
			input-enable;
			bias-pull-up = <MTK_PUPD_SET_R1R0_01>;
		};
	};

	i2c0_pins: i2c0-pins {
		pins-bus {
			pinmux = <PINMUX_GPIO51__FUNC_SCL0>,
				 <PINMUX_GPIO52__FUNC_SDA0>;
			bias-pull-up;
		};
	};

	i2c1_pins: i2c1-pins {
		pins-bus {
			pinmux = <PINMUX_GPIO61__FUNC_SCL1>,
				 <PINMUX_GPIO62__FUNC_SDA1>;
			bias-pull-up;
		};
	};

	touch_pins: touch-pins {
		pins-irq {
			pinmux = <PINMUX_GPIO1__FUNC_GPIO1>;
			input-enable;
			bias-pull-up;
		};

		pins-reset {
			pinmux = <PINMUX_GPIO2__FUNC_GPIO2>;
			output-high;
		};
	};

	i2c6_pins: i2c6-pins {
		pins-bus {
			pinmux = <PINMUX_GPIO45__FUNC_SCL6>,
				 <PINMUX_GPIO46__FUNC_SDA6>;
			bias-pull-up;
		};
	};

	fan_pins: fan-pins {
		pins-tach {
			pinmux = <PINMUX_GPIO40__FUNC_GPIO40>;
			input-enable;
			bias-pull-up;
		};
	};

	pwm0_pins: pwm0-pins {
		pins-fan {
			pinmux = <PINMUX_GPIO26__FUNC_PWM_0>;
			bias-pull-down;
		};
	};

	stick_led_pins: stick-led-pins {
		pins-data {
			pinmux = <PINMUX_GPIO122__FUNC_PWM_1>,
				 <PINMUX_GPIO124__FUNC_PWM_2>;
			bias-disable;
		};
	};

	/* stock drive strength and pulls */
	mmc1_pins: mmc1-pins {
		pins-cmd-dat {
			pinmux = <PINMUX_GPIO135__FUNC_MSDC1_CMD>,
				 <PINMUX_GPIO137__FUNC_MSDC1_DAT0>,
				 <PINMUX_GPIO139__FUNC_MSDC1_DAT1>,
				 <PINMUX_GPIO138__FUNC_MSDC1_DAT2>,
				 <PINMUX_GPIO136__FUNC_MSDC1_DAT3>;
			bias-pull-up = <MTK_PUPD_SET_R1R0_10>;
			drive-strength = <8>;
		};

		pins-clk {
			pinmux = <PINMUX_GPIO134__FUNC_MSDC1_CLK>;
			bias-pull-down = <MTK_PUPD_SET_R1R0_10>;
			drive-strength = <8>;
		};
	};

	/* stock drive strength and pulls */
	mmc0_pins: mmc0-pins {
		pins-cmd-dat {
			pinmux = <PINMUX_GPIO167__FUNC_MSDC0_CMD>,
				 <PINMUX_GPIO168__FUNC_MSDC0_DAT0>,
				 <PINMUX_GPIO172__FUNC_MSDC0_DAT1>,
				 <PINMUX_GPIO169__FUNC_MSDC0_DAT2>,
				 <PINMUX_GPIO177__FUNC_MSDC0_DAT3>,
				 <PINMUX_GPIO170__FUNC_MSDC0_DAT4>,
				 <PINMUX_GPIO173__FUNC_MSDC0_DAT5>,
				 <PINMUX_GPIO171__FUNC_MSDC0_DAT6>,
				 <PINMUX_GPIO174__FUNC_MSDC0_DAT7>,
				 <PINMUX_GPIO178__FUNC_MSDC0_RSTB>;
			bias-pull-up = <MTK_PUPD_SET_R1R0_01>;
			drive-strength = <10>;
		};

		pins-clk-ds {
			pinmux = <PINMUX_GPIO176__FUNC_MSDC0_CLK>,
				 <PINMUX_GPIO175__FUNC_MSDC0_DSL>;
			bias-pull-down = <MTK_PUPD_SET_R1R0_10>;
			drive-strength = <10>;
		};
	};
};

/* roles follow the MT6360 Type-C port; VBUS comes from the MT6360 boost */
&ssusb {
	vusb33-supply = <&mt6359_vusb>;
	dr_mode = "otg";
	maximum-speed = "high-speed";
	usb-role-switch;
	role-switch-default-mode = "peripheral";
	status = "okay";

	port {
		ssusb_hs_ep: endpoint {
			remote-endpoint = <&typec_hs_ep>;
		};
	};
};

&xhci {
	status = "okay";
};
